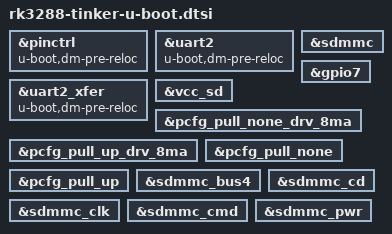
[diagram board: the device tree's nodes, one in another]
// SPDX-License-Identifier: GPL-2.0+
/*
 * Copyright (C) 2019 Rockchip Electronics Co., Ltd
 */

#include "rk3288-u-boot.dtsi"

&pinctrl {
	u-boot,dm-pre-reloc;
};

&uart2 {
	u-boot,dm-pre-reloc;
};

&uart2_xfer {
	u-boot,dm-pre-reloc;
};

&sdmmc {
	u-boot,dm-spl;
};

&gpio7 {
	u-boot,dm-spl;
};

&vcc_sd {
	u-boot,dm-spl;
};

&pcfg_pull_none_drv_8ma {
	u-boot,dm-spl;
};

&pcfg_pull_up_drv_8ma {
	u-boot,dm-spl;
};

&pcfg_pull_none {
	u-boot,dm-spl;
};

&pcfg_pull_up {
	u-boot,dm-spl;
};

&sdmmc_bus4 {
	u-boot,dm-spl;
};

&sdmmc_cd {
	u-boot,dm-spl;
};

&sdmmc_clk {
	u-boot,dm-spl;
};

&sdmmc_cmd {
	u-boot,dm-spl;
};

&sdmmc_pwr {
	u-boot,dm-spl;
};
